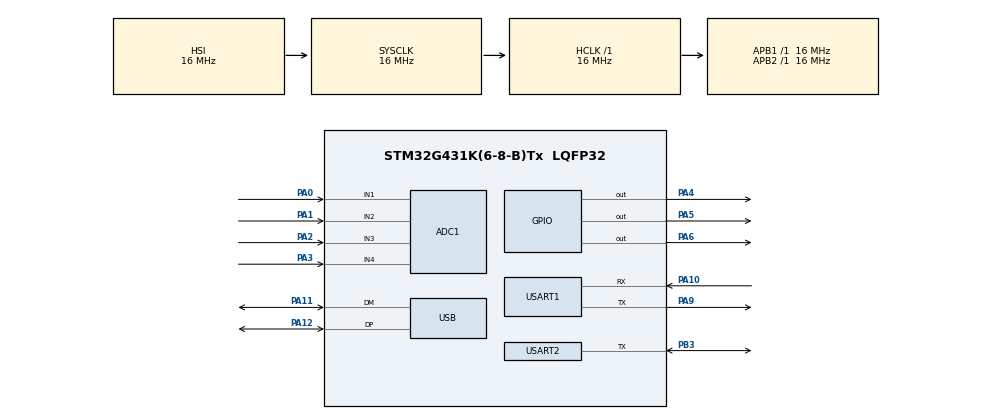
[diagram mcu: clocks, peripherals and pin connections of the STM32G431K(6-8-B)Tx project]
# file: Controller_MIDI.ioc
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ADC1.Channel-0\#ChannelRegularConversion=ADC_CHANNEL_1
ADC1.NbrOfConversionFlag=1
ADC1.OffsetNumber-0\#ChannelRegularConversion=ADC_OFFSET_NONE
ADC1.Rank-0\#ChannelRegularConversion=1
ADC1.SamplingTime-0\#ChannelRegularConversion=ADC_SAMPLETIME_2CYCLES_5
ADC1.master=1
Mcu.Family=STM32G4
Mcu.Name=STM32G431K(6-8-B)Tx
Mcu.Package=LQFP32
NVIC.PriorityGroup=NVIC_PRIORITYGROUP_4
PA0.Mode=IN1-Single-Ended
PA0.Signal=ADC1_IN1
PA1.Mode=IN2-Single-Ended
PA1.Signal=ADC1_IN2
PA10.Mode=Asynchronous
PA10.Signal=USART1_RX
PA11.Mode=Device
PA11.Signal=USB_DM
PA12.Mode=Device
PA12.Signal=USB_DP
PA13.Mode=Serial_Wire
PA13.Signal=SYS_JTMS-SWDIO
PA14.Mode=Serial_Wire
PA14.Signal=SYS_JTCK-SWCLK
PA2.Mode=IN3-Single-Ended
PA2.Signal=ADC1_IN3
PA3.Mode=IN4-Single-Ended
PA3.Signal=ADC1_IN4
PA4.Signal=GPIO_Output
PA5.Signal=GPIO_Output
PA6.Signal=GPIO_Output
PA9.Mode=Asynchronous
PA9.Signal=USART1_TX
PB3.Mode=Half_duplex(single_wire_mode)
PB3.Signal=USART2_TX
ProjectManager.HeapSize=0x200
ProjectManager.StackSize=0x400
ProjectManager.TargetToolchain=STM32CubeIDE
RCC.AHBFreq_Value=16000000
RCC.APB1Freq_Value=16000000
RCC.APB1TimFreq_Value=16000000
RCC.APB2Freq_Value=16000000
RCC.APB2TimFreq_Value=16000000
RCC.CortexFreq_Value=16000000
RCC.EXTERNAL_CLOCK_VALUE=12288000
RCC.HCLKFreq_Value=16000000
RCC.HSE_VALUE=8000000
RCC.HSI48_VALUE=48000000
RCC.HSI_VALUE=16000000
RCC.LSE_VALUE=32768
RCC.SYSCLKFreq_VALUE=16000000
RCC.USBFreq_Value=64000000
RCC.VCOOutputFreq_Value=128000000
USART1.VirtualMode-Asynchronous=VM_ASYNC
USART2.VirtualMode-Half_duplex(single_wire_mode)=VM_ASYNC
board=custom

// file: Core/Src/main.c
/* USER CODE BEGIN Header */
/**
  ******************************************************************************
  * @file           : main.c
  * @brief          : Main program body
  ******************************************************************************
  * @attention
  *
  * Copyright (c) 2024 STMicroelectronics.
  * All rights reserved.
  *
  * This software is licensed under terms that can be found in the LICENSE file
  * in the root directory of this software component.
  * If no LICENSE file comes with this software, it is provided AS-IS.
  *
  ******************************************************************************
  */
/* USER CODE END Header */
#include "main.h"

/* USER CODE BEGIN Includes */
#include "studentwork.h"
/* USER CODE END Includes */

ADC_HandleTypeDef hadc1;
ADC_HandleTypeDef hadc2;
ADC_HandleTypeDef hadc3;
ADC_HandleTypeDef hadc4;

UART_HandleTypeDef huart1;
UART_HandleTypeDef huart2;

PCD_HandleTypeDef hpcd_USB_FS;

void SystemClock_Config(void);
static void MX_GPIO_Init(void);
static void MX_ADC1_Init(void);
static void MX_USART1_UART_Init(void);
static void MX_USART2_UART_Init(void);
static void MX_USB_PCD_Init(void);

int main(void)
{

  /* MCU Configuration--------------------------------------------------------*/

  /* Reset of all peripherals, Initializes the Flash interface and the Systick. */
  HAL_Init();

  /* Configure the system clock */
  SystemClock_Config();

  /* Initialize all configured peripherals */
  MX_GPIO_Init();
  MX_ADC1_Init();
  MX_USART1_UART_Init();
  MX_USART2_UART_Init();
  MX_USB_PCD_Init();
  /* USER CODE BEGIN 2 */
  setup();
  /* USER CODE END 2 */

  /* Infinite loop */
  /* USER CODE BEGIN WHILE */
  while (1)
  {
	  loop();
    /* USER CODE END WHILE */

  }
}

void SystemClock_Config(void)
{
  RCC_OscInitTypeDef RCC_OscInitStruct = {0};
  RCC_ClkInitTypeDef RCC_ClkInitStruct = {0};

  /** Configure the main internal regulator output voltage
  */
  HAL_PWREx_ControlVoltageScaling(PWR_REGULATOR_VOLTAGE_SCALE1);

  /** Initializes the RCC Oscillators according to the specified parameters
  * in the RCC_OscInitTypeDef structure.
  */
  RCC_OscInitStruct.OscillatorType = RCC_OSCILLATORTYPE_HSI;
  RCC_OscInitStruct.HSIState = RCC_HSI_ON;
  RCC_OscInitStruct.HSICalibrationValue = RCC_HSICALIBRATION_DEFAULT;
  RCC_OscInitStruct.PLL.PLLState = RCC_PLL_ON;
  RCC_OscInitStruct.PLL.PLLSource = RCC_PLLSOURCE_HSI;
  RCC_OscInitStruct.PLL.PLLM = RCC_PLLM_DIV1;
  RCC_OscInitStruct.PLL.PLLN = 8;
  RCC_OscInitStruct.PLL.PLLP = RCC_PLLP_DIV2;
  RCC_OscInitStruct.PLL.PLLQ = RCC_PLLQ_DIV2;
  RCC_OscInitStruct.PLL.PLLR = RCC_PLLR_DIV2;
  if (HAL_RCC_OscConfig(&RCC_OscInitStruct) != HAL_OK)
  {
    Error_Handler();
  }

  /** Initializes the CPU, AHB and APB buses clocks
  */
  RCC_ClkInitStruct.ClockType = RCC_CLOCKTYPE_HCLK|RCC_CLOCKTYPE_SYSCLK
                              |RCC_CLOCKTYPE_PCLK1|RCC_CLOCKTYPE_PCLK2;
  RCC_ClkInitStruct.SYSCLKSource = RCC_SYSCLKSOURCE_HSI;
  RCC_ClkInitStruct.AHBCLKDivider = RCC_SYSCLK_DIV1;
  RCC_ClkInitStruct.APB1CLKDivider = RCC_HCLK_DIV1;
  RCC_ClkInitStruct.APB2CLKDivider = RCC_HCLK_DIV1;

  if (HAL_RCC_ClockConfig(&RCC_ClkInitStruct, FLASH_LATENCY_0) != HAL_OK)
  {
    Error_Handler();
  }
}

static void MX_ADC1_Init(void)
{

  ADC_MultiModeTypeDef multimode = {0};
  ADC_ChannelConfTypeDef sConfig = {0};

  /** Common config
  */
  hadc1.Instance = ADC1;
  hadc1.Init.ClockPrescaler = ADC_CLOCK_SYNC_PCLK_DIV2;
  hadc1.Init.Resolution = ADC_RESOLUTION_12B;
  hadc1.Init.DataAlign = ADC_DATAALIGN_RIGHT;
  hadc1.Init.GainCompensation = 0;
  hadc1.Init.ScanConvMode = ADC_SCAN_DISABLE;
  hadc1.Init.EOCSelection = ADC_EOC_SINGLE_CONV;
  hadc1.Init.LowPowerAutoWait = DISABLE;
  hadc1.Init.ContinuousConvMode = DISABLE;
  hadc1.Init.NbrOfConversion = 1;
  hadc1.Init.DiscontinuousConvMode = DISABLE;
  hadc1.Init.ExternalTrigConv = ADC_SOFTWARE_START;
  hadc1.Init.ExternalTrigConvEdge = ADC_EXTERNALTRIGCONVEDGE_NONE;
  hadc1.Init.DMAContinuousRequests = DISABLE;
  hadc1.Init.Overrun = ADC_OVR_DATA_PRESERVED;
  hadc1.Init.OversamplingMode = DISABLE;
  if (HAL_ADC_Init(&hadc1) != HAL_OK)
  {
    Error_Handler();
  }

  /** Configure the ADC multi-mode
  */
  multimode.Mode = ADC_MODE_INDEPENDENT;
  if (HAL_ADCEx_MultiModeConfigChannel(&hadc1, &multimode) != HAL_OK)
  {
    Error_Handler();
  }

  /** Configure Regular Channel
  */
  sConfig.Channel = ADC_CHANNEL_1;
  sConfig.Rank = ADC_REGULAR_RANK_1;
  sConfig.SamplingTime = ADC_SAMPLETIME_2CYCLES_5;
  sConfig.SingleDiff = ADC_SINGLE_ENDED;
  sConfig.OffsetNumber = ADC_OFFSET_NONE;
  sConfig.Offset = 0;
  if (HAL_ADC_ConfigChannel(&hadc1, &sConfig) != HAL_OK)
  {
    Error_Handler();
  }

}

static void MX_USART1_UART_Init(void)
{

  huart1.Instance = USART1;
  huart1.Init.BaudRate = 115200;
  huart1.Init.WordLength = UART_WORDLENGTH_8B;
  huart1.Init.StopBits = UART_STOPBITS_1;
  huart1.Init.Parity = UART_PARITY_NONE;
  huart1.Init.Mode = UART_MODE_TX_RX;
  huart1.Init.HwFlowCtl = UART_HWCONTROL_NONE;
  huart1.Init.OverSampling = UART_OVERSAMPLING_16;
  huart1.Init.OneBitSampling = UART_ONE_BIT_SAMPLE_DISABLE;
  huart1.Init.ClockPrescaler = UART_PRESCALER_DIV1;
  huart1.AdvancedInit.AdvFeatureInit = UART_ADVFEATURE_NO_INIT;
  if (HAL_UART_Init(&huart1) != HAL_OK)
  {
    Error_Handler();
  }
  if (HAL_UARTEx_SetTxFifoThreshold(&huart1, UART_TXFIFO_THRESHOLD_1_8) != HAL_OK)
  {
    Error_Handler();
  }
  if (HAL_UARTEx_SetRxFifoThreshold(&huart1, UART_RXFIFO_THRESHOLD_1_8) != HAL_OK)
  {
    Error_Handler();
  }
  if (HAL_UARTEx_DisableFifoMode(&huart1) != HAL_OK)
  {
    Error_Handler();
  }

}

static void MX_USART2_UART_Init(void)
{

  huart2.Instance = USART2;
  huart2.Init.BaudRate = 115200;
  huart2.Init.WordLength = UART_WORDLENGTH_8B;
  huart2.Init.StopBits = UART_STOPBITS_1;
  huart2.Init.Parity = UART_PARITY_NONE;
  huart2.Init.Mode = UART_MODE_TX_RX;
  huart2.Init.HwFlowCtl = UART_HWCONTROL_NONE;
  huart2.Init.OverSampling = UART_OVERSAMPLING_16;
  huart2.Init.OneBitSampling = UART_ONE_BIT_SAMPLE_DISABLE;
  huart2.Init.ClockPrescaler = UART_PRESCALER_DIV1;
  huart2.AdvancedInit.AdvFeatureInit = UART_ADVFEATURE_NO_INIT;
  if (HAL_HalfDuplex_Init(&huart2) != HAL_OK)
  {
    Error_Handler();
  }
  if (HAL_UARTEx_SetTxFifoThreshold(&huart2, UART_TXFIFO_THRESHOLD_1_8) != HAL_OK)
  {
    Error_Handler();
  }
  if (HAL_UARTEx_SetRxFifoThreshold(&huart2, UART_RXFIFO_THRESHOLD_1_8) != HAL_OK)
  {
    Error_Handler();
  }
  if (HAL_UARTEx_DisableFifoMode(&huart2) != HAL_OK)
  {
    Error_Handler();
  }

}

static void MX_USB_PCD_Init(void)
{

  hpcd_USB_FS.Instance = USB;
  hpcd_USB_FS.Init.dev_endpoints = 8;
  hpcd_USB_FS.Init.speed = PCD_SPEED_FULL;
  hpcd_USB_FS.Init.phy_itface = PCD_PHY_EMBEDDED;
  hpcd_USB_FS.Init.Sof_enable = DISABLE;
  hpcd_USB_FS.Init.low_power_enable = DISABLE;
  hpcd_USB_FS.Init.lpm_enable = DISABLE;
  hpcd_USB_FS.Init.battery_charging_enable = DISABLE;
  if (HAL_PCD_Init(&hpcd_USB_FS) != HAL_OK)
  {
    Error_Handler();
  }

}

static void MX_GPIO_Init(void)
{
  GPIO_InitTypeDef GPIO_InitStruct = {0};

  /* GPIO Ports Clock Enable */
  __HAL_RCC_GPIOA_CLK_ENABLE();
  __HAL_RCC_GPIOB_CLK_ENABLE();

  /*Configure GPIO pin Output Level */
  HAL_GPIO_WritePin(GPIOA, GPIO_PIN_4|GPIO_PIN_5|GPIO_PIN_6, GPIO_PIN_RESET);

  /*Configure GPIO pins : PA4 PA5 PA6 */
  GPIO_InitStruct.Pin = GPIO_PIN_4|GPIO_PIN_5|GPIO_PIN_6;
  GPIO_InitStruct.Mode = GPIO_MODE_OUTPUT_PP;
  GPIO_InitStruct.Pull = GPIO_NOPULL;
  GPIO_InitStruct.Speed = GPIO_SPEED_FREQ_LOW;
  HAL_GPIO_Init(GPIOA, &GPIO_InitStruct);

}

void Error_Handler(void)
{
  __disable_irq();
  while (1)
  {
  }
}
